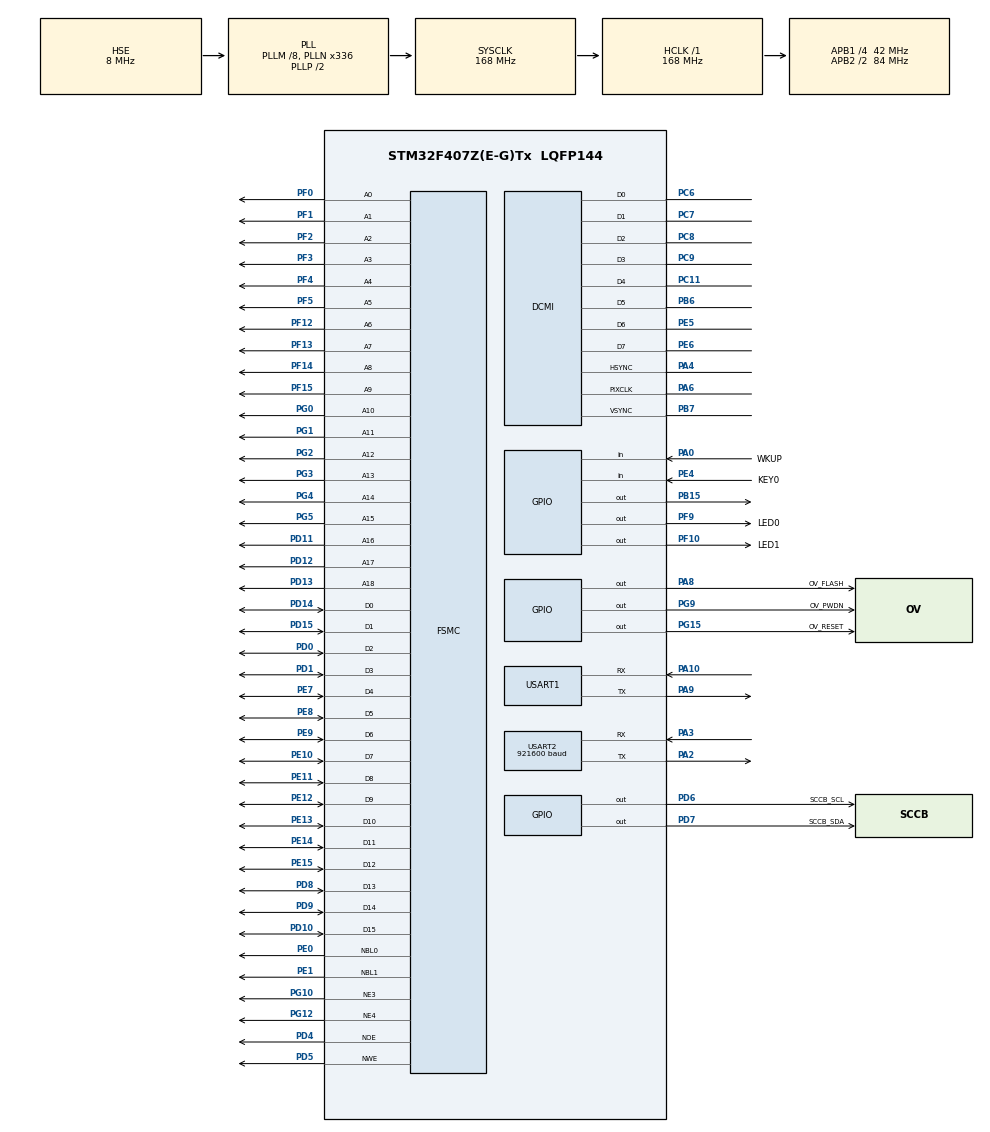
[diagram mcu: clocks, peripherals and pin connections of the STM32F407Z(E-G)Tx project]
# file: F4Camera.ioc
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DCMI.JPEGMode=DCMI_JPEG_DISABLE
DCMI.PCKPolarity=DCMI_PCKPOLARITY_RISING
Dma.DCMI.0.Direction=DMA_PERIPH_TO_MEMORY
Dma.DCMI.0.FIFOMode=DMA_FIFOMODE_ENABLE
Dma.DCMI.0.FIFOThreshold=DMA_FIFO_THRESHOLD_HALFFULL
Dma.DCMI.0.Instance=DMA2_Stream1
Dma.DCMI.0.MemBurst=DMA_MBURST_SINGLE
Dma.DCMI.0.MemDataAlignment=DMA_MDATAALIGN_WORD
Dma.DCMI.0.MemInc=DMA_MINC_ENABLE
Dma.DCMI.0.Mode=DMA_NORMAL
Dma.DCMI.0.PeriphBurst=DMA_PBURST_SINGLE
Dma.DCMI.0.PeriphDataAlignment=DMA_PDATAALIGN_WORD
Dma.DCMI.0.PeriphInc=DMA_PINC_DISABLE
Dma.DCMI.0.Priority=DMA_PRIORITY_VERY_HIGH
Dma.MEMTOMEM.1.Direction=DMA_MEMORY_TO_MEMORY
Dma.MEMTOMEM.1.FIFOMode=DMA_FIFOMODE_ENABLE
Dma.MEMTOMEM.1.FIFOThreshold=DMA_FIFO_THRESHOLD_FULL
Dma.MEMTOMEM.1.Instance=DMA2_Stream0
Dma.MEMTOMEM.1.MemBurst=DMA_MBURST_SINGLE
Dma.MEMTOMEM.1.MemDataAlignment=DMA_MDATAALIGN_HALFWORD
Dma.MEMTOMEM.1.MemInc=DMA_MINC_DISABLE
Dma.MEMTOMEM.1.Mode=DMA_NORMAL
Dma.MEMTOMEM.1.PeriphBurst=DMA_PBURST_SINGLE
Dma.MEMTOMEM.1.PeriphDataAlignment=DMA_PDATAALIGN_HALFWORD
Dma.MEMTOMEM.1.PeriphInc=DMA_PINC_ENABLE
Dma.MEMTOMEM.1.Priority=DMA_PRIORITY_HIGH
Dma.Request0=DCMI
Dma.Request1=MEMTOMEM
FSMC.AddressSetupTime3=3
FSMC.BusTurnAroundDuration3=0
FSMC.BusTurnAroundDuration4=0
FSMC.DataSetupTime3=9
FSMC.DataSetupTime4=60
FSMC.ExtendedAddressSetupTime4=9
FSMC.ExtendedBusTurnAroundDuration4=0
FSMC.ExtendedDataSetupTime4=9
FSMC.ExtendedMode4=FSMC_EXTENDED_MODE_ENABLE
FSMC.NSBank4=FSMC_NORSRAM_BANK4
FSMC.WriteOperation3=FSMC_WRITE_OPERATION_ENABLE
FSMC.WriteOperation4=FSMC_WRITE_OPERATION_ENABLE
Mcu.Family=STM32F4
Mcu.Name=STM32F407Z(E-G)Tx
Mcu.Package=LQFP144
NVIC.DCMI_IRQn=true\:0\:0\:false\:false\:true\:true\:true\:true
NVIC.DMA2_Stream0_IRQn=true\:2\:0\:true\:false\:true\:true\:true\:true
NVIC.DMA2_Stream1_IRQn=true\:0\:0\:true\:false\:true\:false\:true\:true
NVIC.PriorityGroup=NVIC_PRIORITYGROUP_4
PA0-WKUP.GPIO_Label=WKUP
PA0-WKUP.GPIO_PuPd=GPIO_PULLDOWN
PA0-WKUP.Signal=GPIO_Input
PA10.Mode=Asynchronous
PA10.Signal=USART1_RX
PA13.Mode=Serial_Wire
PA13.Signal=SYS_JTMS-SWDIO
PA14.Mode=Serial_Wire
PA14.Signal=SYS_JTCK-SWCLK
PA2.Mode=Asynchronous
PA2.Signal=USART2_TX
PA3.Mode=Asynchronous
PA3.Signal=USART2_RX
PA4.GPIO_PuPd=GPIO_PULLUP
PA4.Mode=Slave_8_bits_External_Synchro
PA4.Signal=DCMI_HSYNC
PA6.GPIO_PuPd=GPIO_PULLUP
PA6.Mode=Slave_8_bits_External_Synchro
PA6.Signal=DCMI_PIXCLK
PA8.GPIO_Label=OV_FLASH
PA8.GPIO_Speed=GPIO_SPEED_FREQ_HIGH
PA8.Signal=GPIO_Output
PA9.Mode=Asynchronous
PA9.Signal=USART1_TX
PB15.GPIO_Speed=GPIO_SPEED_FREQ_HIGH
PB15.Signal=GPIO_Output
PB6.GPIO_PuPd=GPIO_PULLUP
PB6.Mode=Slave_8_bits_External_Synchro
PB6.Signal=DCMI_D5
PB7.GPIO_PuPd=GPIO_PULLUP
PB7.Mode=Slave_8_bits_External_Synchro
PB7.Signal=DCMI_VSYNC
PC11.GPIO_PuPd=GPIO_PULLUP
PC11.Mode=Slave_8_bits_External_Synchro
PC11.Signal=DCMI_D4
PC6.GPIO_PuPd=GPIO_PULLUP
PC6.Mode=Slave_8_bits_External_Synchro
PC6.Signal=DCMI_D0
PC7.GPIO_PuPd=GPIO_PULLUP
PC7.Mode=Slave_8_bits_External_Synchro
PC7.Signal=DCMI_D1
PC8.GPIO_PuPd=GPIO_PULLUP
PC8.Mode=Slave_8_bits_External_Synchro
PC8.Signal=DCMI_D2
PC9.GPIO_PuPd=GPIO_PULLUP
PC9.Mode=Slave_8_bits_External_Synchro
PC9.Signal=DCMI_D3
PD0.Signal=FSMC_D2_DA2
PD1.Signal=FSMC_D3_DA3
PD10.Signal=FSMC_D15_DA15
PD11.Signal=FSMC_A16_CLE
PD12.Signal=FSMC_A17_ALE
PD13.Signal=FSMC_A18
PD14.Signal=FSMC_D0_DA0
PD15.Signal=FSMC_D1_DA1
PD4.Signal=FSMC_NOE
PD5.Signal=FSMC_NWE
PD6.GPIO_Label=SCCB_SCL
PD6.GPIO_PuPd=GPIO_PULLUP
PD6.GPIO_Speed=GPIO_SPEED_FREQ_HIGH
PD6.PinState=GPIO_PIN_SET
PD6.Signal=GPIO_Output
PD7.GPIO_Label=SCCB_SDA
PD7.GPIO_ModeDefaultOutputPP=GPIO_MODE_OUTPUT_OD
PD7.GPIO_PuPd=GPIO_PULLUP
PD7.PinState=GPIO_PIN_SET
PD7.Signal=GPIO_Output
PD8.Signal=FSMC_D13_DA13
PD9.Signal=FSMC_D14_DA14
PE0.Signal=FSMC_NBL0
PE1.Signal=FSMC_NBL1
PE10.Signal=FSMC_D7_DA7
PE11.Signal=FSMC_D8_DA8
PE12.Signal=FSMC_D9_DA9
PE13.Signal=FSMC_D10_DA10
PE14.Signal=FSMC_D11_DA11
PE15.Signal=FSMC_D12_DA12
PE4.GPIO_Label=KEY0
PE4.GPIO_PuPd=GPIO_PULLUP
PE4.Signal=GPIO_Input
PE5.GPIO_PuPd=GPIO_PULLUP
PE5.Mode=Slave_8_bits_External_Synchro
PE5.Signal=DCMI_D6
PE6.GPIO_PuPd=GPIO_PULLUP
PE6.Mode=Slave_8_bits_External_Synchro
PE6.Signal=DCMI_D7
PE7.Signal=FSMC_D4_DA4
PE8.Signal=FSMC_D5_DA5
PE9.Signal=FSMC_D6_DA6
PF0.Signal=FSMC_A0
PF1.Signal=FSMC_A1
PF10.GPIO_Label=LED1
PF10.GPIO_Speed=GPIO_SPEED_FREQ_HIGH
PF10.PinState=GPIO_PIN_SET
PF10.Signal=GPIO_Output
PF12.Signal=FSMC_A6
PF13.Signal=FSMC_A7
PF14.Signal=FSMC_A8
PF15.Signal=FSMC_A9
PF2.Signal=FSMC_A2
PF3.Signal=FSMC_A3
PF4.Signal=FSMC_A4
PF5.Signal=FSMC_A5
PF9.GPIO_Label=LED0
PF9.GPIO_Speed=GPIO_SPEED_FREQ_HIGH
PF9.PinState=GPIO_PIN_SET
PF9.Signal=GPIO_Output
PG0.Signal=FSMC_A10
PG1.Signal=FSMC_A11
PG10.Mode=NorPsramChipSelect3_3
PG10.Signal=FSMC_NE3
PG12.Mode=NorPsramChipSelect4_4
PG12.Signal=FSMC_NE4
PG15.GPIO_Label=OV_RESET
PG15.GPIO_PuPd=GPIO_PULLUP
PG15.GPIO_Speed=GPIO_SPEED_FREQ_HIGH
PG15.PinState=GPIO_PIN_SET
PG15.Signal=GPIO_Output
PG2.Signal=FSMC_A12
PG3.Signal=FSMC_A13
PG4.Signal=FSMC_A14
PG5.Signal=FSMC_A15
PG9.GPIO_Label=OV_PWDN
PG9.GPIO_PuPd=GPIO_PULLUP
PG9.GPIO_Speed=GPIO_SPEED_FREQ_HIGH
PG9.Signal=GPIO_Output
PH0-OSC_IN.Mode=HSE-External-Oscillator
PH0-OSC_IN.Signal=RCC_OSC_IN
PH1-OSC_OUT.Mode=HSE-External-Oscillator
PH1-OSC_OUT.Signal=RCC_OSC_OUT
ProjectManager.HeapSize=0x200
ProjectManager.StackSize=0x1000
ProjectManager.TargetToolchain=MDK-ARM V5.32
RCC.48MHZClocksFreq_Value=84000000
RCC.AHBFreq_Value=168000000
RCC.APB1CLKDivider=RCC_HCLK_DIV4
RCC.APB1Freq_Value=42000000
RCC.APB1TimFreq_Value=84000000
RCC.APB2CLKDivider=RCC_HCLK_DIV2
RCC.APB2Freq_Value=84000000
RCC.APB2TimFreq_Value=168000000
RCC.CortexFreq_Value=168000000
RCC.HCLKFreq_Value=168000000
RCC.HSE_VALUE=8000000
RCC.HSI_VALUE=16000000
RCC.LSE_VALUE=32768
RCC.PLLM=8
RCC.PLLN=336
RCC.PLLSourceVirtual=RCC_PLLSOURCE_HSE
RCC.SYSCLKFreq_VALUE=168000000
RCC.SYSCLKSource=RCC_SYSCLKSOURCE_PLLCLK
RCC.VCOOutputFreq_Value=336000000
SH.FSMC_A0.0=FSMC_A0,8b-a4
SH.FSMC_A0.1=FSMC_A0,19b-a3
SH.FSMC_A1.0=FSMC_A1,8b-a4
SH.FSMC_A1.1=FSMC_A1,19b-a3
SH.FSMC_A10.0=FSMC_A10,19b-a3
SH.FSMC_A11.0=FSMC_A11,19b-a3
SH.FSMC_A12.0=FSMC_A12,19b-a3
SH.FSMC_A13.0=FSMC_A13,19b-a3
SH.FSMC_A14.0=FSMC_A14,19b-a3
SH.FSMC_A15.0=FSMC_A15,19b-a3
SH.FSMC_A16_CLE.0=FSMC_A16,19b-a3
SH.FSMC_A17_ALE.0=FSMC_A17,19b-a3
SH.FSMC_A18.0=FSMC_A18,19b-a3
SH.FSMC_A2.0=FSMC_A2,8b-a4
SH.FSMC_A2.1=FSMC_A2,19b-a3
SH.FSMC_A3.0=FSMC_A3,8b-a4
SH.FSMC_A3.1=FSMC_A3,19b-a3
SH.FSMC_A4.0=FSMC_A4,8b-a4
SH.FSMC_A4.1=FSMC_A4,19b-a3
SH.FSMC_A5.0=FSMC_A5,8b-a4
SH.FSMC_A5.1=FSMC_A5,19b-a3
SH.FSMC_A6.0=FSMC_A6,8b-a4
SH.FSMC_A6.1=FSMC_A6,19b-a3
SH.FSMC_A7.0=FSMC_A7,8b-a4
SH.FSMC_A7.1=FSMC_A7,19b-a3
SH.FSMC_A8.0=FSMC_A8,19b-a3
SH.FSMC_A9.0=FSMC_A9,19b-a3
SH.FSMC_D0_DA0.0=FSMC_D0,16b-d4
SH.FSMC_D0_DA0.1=FSMC_D0,16b-d3
SH.FSMC_D10_DA10.0=FSMC_D10,16b-d4
SH.FSMC_D10_DA10.1=FSMC_D10,16b-d3
SH.FSMC_D11_DA11.0=FSMC_D11,16b-d4
SH.FSMC_D11_DA11.1=FSMC_D11,16b-d3
SH.FSMC_D12_DA12.0=FSMC_D12,16b-d4
SH.FSMC_D12_DA12.1=FSMC_D12,16b-d3
SH.FSMC_D13_DA13.0=FSMC_D13,16b-d4
SH.FSMC_D13_DA13.1=FSMC_D13,16b-d3
SH.FSMC_D14_DA14.0=FSMC_D14,16b-d4
SH.FSMC_D14_DA14.1=FSMC_D14,16b-d3
SH.FSMC_D15_DA15.0=FSMC_D15,16b-d4
SH.FSMC_D15_DA15.1=FSMC_D15,16b-d3
SH.FSMC_D1_DA1.0=FSMC_D1,16b-d4
SH.FSMC_D1_DA1.1=FSMC_D1,16b-d3
SH.FSMC_D2_DA2.0=FSMC_D2,16b-d4
SH.FSMC_D2_DA2.1=FSMC_D2,16b-d3
SH.FSMC_D3_DA3.0=FSMC_D3,16b-d4
SH.FSMC_D3_DA3.1=FSMC_D3,16b-d3
SH.FSMC_D4_DA4.0=FSMC_D4,16b-d4
SH.FSMC_D4_DA4.1=FSMC_D4,16b-d3
SH.FSMC_D5_DA5.0=FSMC_D5,16b-d4
SH.FSMC_D5_DA5.1=FSMC_D5,16b-d3
SH.FSMC_D6_DA6.0=FSMC_D6,16b-d4
SH.FSMC_D6_DA6.1=FSMC_D6,16b-d3
SH.FSMC_D7_DA7.0=FSMC_D7,16b-d4
SH.FSMC_D7_DA7.1=FSMC_D7,16b-d3
SH.FSMC_D8_DA8.0=FSMC_D8,16b-d4
SH.FSMC_D8_DA8.1=FSMC_D8,16b-d3
SH.FSMC_D9_DA9.0=FSMC_D9,16b-d4
SH.FSMC_D9_DA9.1=FSMC_D9,16b-d3
SH.FSMC_NBL0.0=FSMC_NBL0,2ByteEnable3
SH.FSMC_NBL1.0=FSMC_NBL1,2ByteEnable3
SH.FSMC_NOE.0=FSMC_NOE,Sram4
SH.FSMC_NOE.1=FSMC_NOE,Sram3
SH.FSMC_NWE.0=FSMC_NWE,Sram4
SH.FSMC_NWE.1=FSMC_NWE,Sram3
USART1.VirtualMode=VM_ASYNC
USART2.BaudRate=921600
USART2.Mode=MODE_TX
USART2.VirtualMode=VM_ASYNC
board=custom

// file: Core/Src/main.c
/* USER CODE BEGIN Header */
/**
  ******************************************************************************
  * @file           : main.c
  * @brief          : Main program body
  ******************************************************************************
  * @attention
  *
  * Copyright (c) 2026 STMicroelectronics.
  * All rights reserved.
  *
  * This software is licensed under terms that can be found in the LICENSE file
  * in the root directory of this software component.
  * If no LICENSE file comes with this software, it is provided AS-IS.
  *
  ******************************************************************************
  */
/* USER CODE END Header */
#include "main.h"
#include "dcmi.h"
#include "dma.h"
#include "usart.h"
#include "gpio.h"
#include "fsmc.h"

/* USER CODE BEGIN Includes */
#include <stdio.h>
#include "camera_app.h"
#include "sram_test.h"
#include "vofa.h"
/* USER CODE END Includes */

void SystemClock_Config(void);

/* USER CODE BEGIN 0 */
#if defined(__ARMCC_VERSION) && (__ARMCC_VERSION >= 6010050)
__asm(".global __use_no_semihosting\n\t");
__asm(".global __ARM_use_no_argv\n\t");
#endif

/* USER CODE END 0 */

int main(void)
{

  /* MCU Configuration--------------------------------------------------------*/

  /* Reset of all peripherals, Initializes the Flash interface and the Systick. */
  HAL_Init();

  /* Configure the system clock */
  SystemClock_Config();

  /* Initialize all configured peripherals */
  MX_GPIO_Init();
  MX_DMA_Init();
  MX_DCMI_Init();
  MX_FSMC_Init();
  MX_USART2_UART_Init();
  MX_USART1_UART_Init();
  /* USER CODE BEGIN 2 */
  SRAM_Test();
  CameraApp_Init();
  /* USER CODE END 2 */

  /* Infinite loop */
  while (1)
  {

    /* USER CODE BEGIN 3 */
    CameraApp_Process();
    Vofa_Process();
  }
  /* USER CODE END 3 */
}

void SystemClock_Config(void)
{
  RCC_OscInitTypeDef RCC_OscInitStruct = {0};
  RCC_ClkInitTypeDef RCC_ClkInitStruct = {0};

  /** Configure the main internal regulator output voltage
  */
  __HAL_RCC_PWR_CLK_ENABLE();
  __HAL_PWR_VOLTAGESCALING_CONFIG(PWR_REGULATOR_VOLTAGE_SCALE1);

  /** Initializes the RCC Oscillators according to the specified parameters
  * in the RCC_OscInitTypeDef structure.
  */
  RCC_OscInitStruct.OscillatorType = RCC_OSCILLATORTYPE_HSE;
  RCC_OscInitStruct.HSEState = RCC_HSE_ON;
  RCC_OscInitStruct.PLL.PLLState = RCC_PLL_ON;
  RCC_OscInitStruct.PLL.PLLSource = RCC_PLLSOURCE_HSE;
  RCC_OscInitStruct.PLL.PLLM = 8;
  RCC_OscInitStruct.PLL.PLLN = 336;
  RCC_OscInitStruct.PLL.PLLP = RCC_PLLP_DIV2;
  RCC_OscInitStruct.PLL.PLLQ = 4;
  if (HAL_RCC_OscConfig(&RCC_OscInitStruct) != HAL_OK)
  {
    Error_Handler();
  }

  /** Initializes the CPU, AHB and APB buses clocks
  */
  RCC_ClkInitStruct.ClockType = RCC_CLOCKTYPE_HCLK|RCC_CLOCKTYPE_SYSCLK
                              |RCC_CLOCKTYPE_PCLK1|RCC_CLOCKTYPE_PCLK2;
  RCC_ClkInitStruct.SYSCLKSource = RCC_SYSCLKSOURCE_PLLCLK;
  RCC_ClkInitStruct.AHBCLKDivider = RCC_SYSCLK_DIV1;
  RCC_ClkInitStruct.APB1CLKDivider = RCC_HCLK_DIV4;
  RCC_ClkInitStruct.APB2CLKDivider = RCC_HCLK_DIV2;

  if (HAL_RCC_ClockConfig(&RCC_ClkInitStruct, FLASH_LATENCY_5) != HAL_OK)
  {
    Error_Handler();
  }
}

/* USER CODE BEGIN 4 */
void HAL_DCMI_FrameEventCallback(DCMI_HandleTypeDef *dcmi_handle)
{
  CameraApp_NotifyFrameEvent(dcmi_handle);
}

void HAL_DCMI_ErrorCallback(DCMI_HandleTypeDef *dcmi_handle)
{
  CameraApp_NotifyError(dcmi_handle);
}

#if defined(__ARMCC_VERSION) && (__ARMCC_VERSION >= 6010050)
FILE __stdout;

int _ttywrch(int ch)
{
  return ch;
}

void _sys_exit(int status)
{
  (void)status;
}

char *_sys_command_string(char *command, int length)
{
  (void)command;
  (void)length;
  return NULL;
}
#endif

/* USER CODE END 4 */

void Error_Handler(void)
{
  __disable_irq();
  while (1)
  {
  }
}
